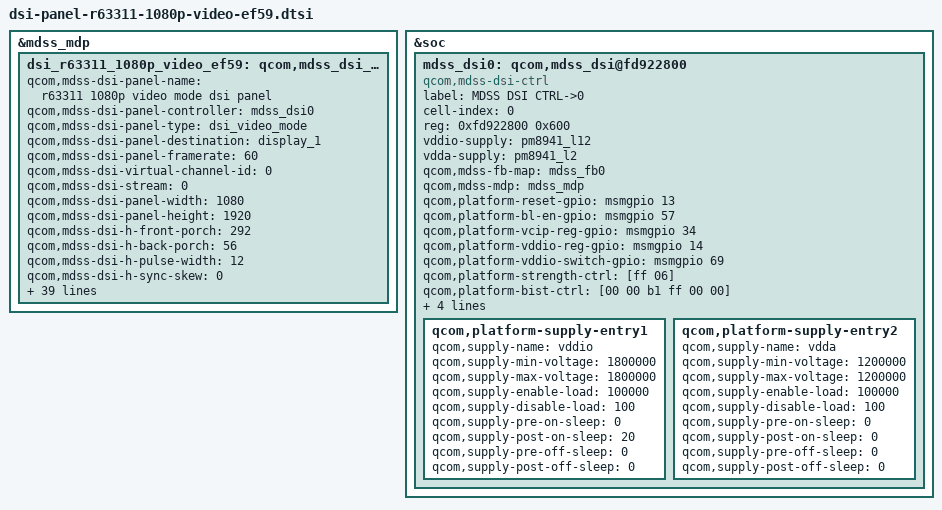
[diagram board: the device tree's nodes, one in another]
/* Copyright (c) 2013, The Linux Foundation. All rights reserved.
 *
 * This program is free software; you can redistribute it and/or modify
 * it under the terms of the GNU General Public License version 2 and
 * only version 2 as published by the Free Software Foundation.
 *
 * This program is distributed in the hope that it will be useful,
 * but WITHOUT ANY WARRANTY; without even the implied warranty of
 * MERCHANTABILITY or FITNESS FOR A PARTICULAR PURPOSE.  See the
 * GNU General Public License for more details.
 */

/*---------------------------------------------------------------------------
 * This file is autogenerated file using gcdb parser. Please do not edit it.
 * Update input XML file to add a new entry or update variable in this file
 * VERSION = "1.0"
 *---------------------------------------------------------------------------*/
&mdss_mdp {
	dsi_r63311_1080p_video_ef59: qcom,mdss_dsi_r63311_1080p_video_ef59 {
		qcom,mdss-dsi-panel-name = "r63311 1080p video mode dsi panel";
		qcom,mdss-dsi-panel-controller = <&mdss_dsi0>;
		qcom,mdss-dsi-panel-type = "dsi_video_mode";
		qcom,mdss-dsi-panel-destination = "display_1";
		qcom,mdss-dsi-panel-framerate = <60>;
		qcom,mdss-dsi-virtual-channel-id = <0>;
		qcom,mdss-dsi-stream = <0>;
		qcom,mdss-dsi-panel-width = <1080>;
		qcom,mdss-dsi-panel-height = <1920>;
		qcom,mdss-dsi-h-front-porch = <292>;
		qcom,mdss-dsi-h-back-porch = <56>;
		qcom,mdss-dsi-h-pulse-width = <12>;
		qcom,mdss-dsi-h-sync-skew = <0>;
		qcom,mdss-dsi-v-back-porch = <4>;
		qcom,mdss-dsi-v-front-porch = <4>;
		qcom,mdss-dsi-v-pulse-width = <2>;
		qcom,mdss-dsi-h-left-border = <0>;
		qcom,mdss-dsi-h-right-border = <0>;
		qcom,mdss-dsi-v-top-border = <0>;
		qcom,mdss-dsi-v-bottom-border = <0>;
		qcom,mdss-dsi-bpp = <24>;
		qcom,mdss-dsi-underflow-color = <0xff>;
		qcom,mdss-dsi-border-color = <0>;
		qcom,mdss-dsi-on-command = [29 01 00 00 00 00 02 b0 00
				05 01 00 00 00 00 02 00 00
				05 01 00 00 00 00 02 00 00
				29 01 00 00 00 00 08 ce 00 38 00 c1 d2 05 01       
				29 01 00 00 00 00 08 b9 0f 18 18 18 9f 1f 80
				29 01 00 00 00 00 08 ba 0f 18 04 40 9f 1f d7
				29 01 00 00 00 00 1a b8 18 80 18 18 cf 1f 00 0c 10 5c 10 ac 10 0c 10 da 6d ff ff 10 67 89 af d6 ff
				13 01 00 00 00 00 02 d6 01
				13 01 00 00 00 00 02 b0 03
				05 01 00 00 00 00 02 00 00
				05 01 00 00 00 00 02 00 00
				39 01 00 00 00 00 03 5e 00 28
				39 01 00 00 00 00 03 51 00 4e
				15 01 00 00 00 00 02 53 2c
				15 01 00 00 00 00 02 55 03
				05 01 00 00 00 00 02 29 00
				05 01 00 00 78 00 02 11 00];
		qcom,mdss-dsi-off-command = [05 01 00 00 14 00 02 28 00
					05 01 00 00 50 00 02 10 00];
		qcom,mdss-dsi-cabc-command = [15 01 00 00 00 00 02 55 03];	
		qcom,mdss-dsi-on-command-state = "dsi_lp_mode";
		qcom,mdss-dsi-off-command-state = "dsi_hs_mode";
		qcom,mdss-dsi-cabc-command-state = "dsi_hs_mode";	
		qcom,mdss-dsi-h-sync-pulse = <1>;
		qcom,mdss-dsi-traffic-mode = "non_burst_sync_event";
		qcom,mdss-dsi-bllp-eof-power-mode;
		qcom,mdss-dsi-bllp-power-mode;
		qcom,mdss-dsi-lane-0-state;
		qcom,mdss-dsi-lane-1-state;
		qcom,mdss-dsi-lane-2-state;
		qcom,mdss-dsi-lane-3-state;
		qcom,mdss-dsi-panel-timings = [b0 23 1b 00 94 93 1e 25 15 03 04 00];
		qcom,mdss-dsi-t-clk-post = <0x1e>;
		qcom,mdss-dsi-t-clk-pre = <0x3a>;
		qcom,mdss-dsi-bl-min-level = <1>;
		qcom,mdss-dsi-bl-max-level = <194>;
		qcom,mdss-dsi-dma-trigger = "trigger_sw";
		qcom,mdss-dsi-mdp-trigger = "none";
		qcom,mdss-dsi-bl-pmic-control-type = "bl_ctrl_dcs";
		qcom,mdss-dsi-reset-sequence = <1 20>, <0 20>, <1 20>;
	};
};

&soc {
	mdss_dsi0: qcom,mdss_dsi@fd922800 {
		compatible = "qcom,mdss-dsi-ctrl";
		label = "MDSS DSI CTRL->0";
		cell-index = <0>;
		reg = <0xfd922800 0x600>;
		vddio-supply = <&pm8941_l12>;
		vdda-supply = <&pm8941_l2>;
		qcom,mdss-fb-map = <&mdss_fb0>;
		qcom,mdss-mdp = <&mdss_mdp>;
		qcom,platform-reset-gpio = <&msmgpio 13 0>;
		qcom,platform-bl-en-gpio = <&msmgpio 57 0>;
		qcom,platform-vcip-reg-gpio = <&msmgpio 34 0>;
		qcom,platform-vddio-reg-gpio = <&msmgpio 14 0>;
		qcom,platform-vddio-switch-gpio = <&msmgpio 69 0>;
		qcom,platform-strength-ctrl = [ff 06];
		qcom,platform-bist-ctrl = [00 00 b1 ff 00 00];
		qcom,platform-regulator-settings = [07 09 03 00 20 00 01];
		qcom,platform-lane-config = [00 00 00 00 00 00 00 01 97
			00 00 00 00 05 00 00 01 97
			00 00 00 00 0a 00 00 01 97
			00 00 00 00 0f 00 00 01 97
			00 c0 00 00 00 00 00 01 bb];
		qcom,platform-supply-entry1 {
				qcom,supply-name = "vddio";
				qcom,supply-min-voltage = <1800000>;
				qcom,supply-max-voltage = <1800000>;
				qcom,supply-enable-load = <100000>;
				qcom,supply-disable-load = <100>;
				qcom,supply-pre-on-sleep = <0>;
				qcom,supply-post-on-sleep = <20>;
				qcom,supply-pre-off-sleep = <0>;
				qcom,supply-post-off-sleep = <0>;
		};
		qcom,platform-supply-entry2 {
				qcom,supply-name = "vdda";
				qcom,supply-min-voltage = <1200000>;
				qcom,supply-max-voltage = <1200000>;
				qcom,supply-enable-load = <100000>;
				qcom,supply-disable-load = <100>;
				qcom,supply-pre-on-sleep = <0>;
				qcom,supply-post-on-sleep = <0>;
				qcom,supply-pre-off-sleep = <0>;
				qcom,supply-post-off-sleep = <0>;
		};
	};	
};

